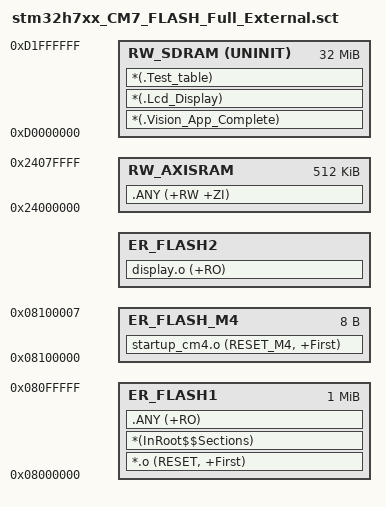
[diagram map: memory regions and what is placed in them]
LR_FLASH1 0x08000000 0x00100000  {    ; load region size_region
  ER_FLASH1 0x08000000 0x00100000  {  ; load address = execution address
    *.o (RESET, +First)
    *(InRoot$$Sections)
    .ANY (+RO)
  }
  RW_AXISRAM 0x24000000 0x00080000  {
    .ANY (+RW +ZI)
  }
  RW_SDRAM 0xD0000000 UNINIT 0x02000000  {  ; RW data
    *(.Vision_App_Complete)
    *(.Lcd_Display)
    *(.Test_table)
  }
}

LR_FLASH2 0x08100000 0x00100000  {
  ER_FLASH_M4 0x08100000 0x0000008 {
    startup_cm4.o (RESET_M4, +First)
  }
  ER_FLASH2 +0 {
    display.o (+RO)
  }
}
